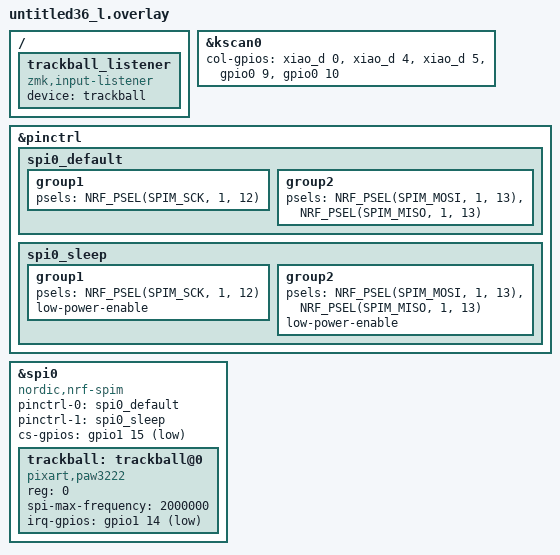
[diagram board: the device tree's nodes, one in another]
#include "untitled36.dtsi"

&kscan0 {
    col-gpios
        = <&xiao_d 0 GPIO_ACTIVE_HIGH>    /* COL0 = D0 = P0.02（小指） */
        , <&xiao_d 4 GPIO_ACTIVE_HIGH>    /* COL1 = D4 = P0.04（薬指） */
        , <&xiao_d 5 GPIO_ACTIVE_HIGH>    /* COL2 = D5 = P0.05（中指） */
        , <&gpio0 9 GPIO_ACTIVE_HIGH>     /* COL3 = P0.09（NFC1・人差し指） */
        , <&gpio0 10 GPIO_ACTIVE_HIGH>    /* COL4 = P0.10（NFC2・内側） */
        ;
};

/ {
    trackball_listener {
        status = "okay";
        compatible = "zmk,input-listener";
        device = <&trackball>;
    };
};

// トラックボールは3線式SPI（MOSI/MISOを1本のSDIOピンで共用）
&pinctrl {
    spi0_default: spi0_default {
        group1 {
            psels = <NRF_PSEL(SPIM_SCK, 1, 12)>;
        };
        group2 {
            psels = <NRF_PSEL(SPIM_MOSI, 1, 13)>,
                <NRF_PSEL(SPIM_MISO, 1, 13)>;
        };
    };

    spi0_sleep: spi0_sleep {
        group1 {
            psels = <NRF_PSEL(SPIM_SCK, 1, 12)>;
            low-power-enable;
        };
        group2 {
            psels = <NRF_PSEL(SPIM_MOSI, 1, 13)>,
                <NRF_PSEL(SPIM_MISO, 1, 13)>;
            low-power-enable;
        };
    };
};

&spi0 {
    compatible = "nordic,nrf-spim";
    status = "okay";
    pinctrl-0 = <&spi0_default>;
    pinctrl-1 = <&spi0_sleep>;
    pinctrl-names = "default", "sleep";
    cs-gpios = <&gpio1 15 GPIO_ACTIVE_LOW>;   /* CS = D10 = P1.15 */

    trackball: trackball@0 {
        status = "okay";
        compatible = "pixart,paw3222";
        reg = <0>;
        spi-max-frequency = <2000000>;
        irq-gpios = <&gpio1 14 (GPIO_ACTIVE_LOW | GPIO_PULL_UP)>;   /* MOTION = D9 = P1.14 */
    };
};
